# NVM Register Definitions: IP-XACT component
VLNV meklort:<PROJECT>:NVM Register Definitions:1.0

## Address spaces and blocks
NVM.NVM: base 0xC0007000, range , width , register

## Registers
Registers are 32-bit, read-write, no defined reset value unless marked. A register's access mark holds for its fields unless they carry their own. Offsets are from the block's base; lines under a group give offsets from that group; [hi:lo] are bit positions; {n}, {i} and the like mark numbered series; 'fields as' and 'values as' point back to an identical list; <NAME> marks a mode.

## NVM.NVM — Device Registers
Base 0xC0007000
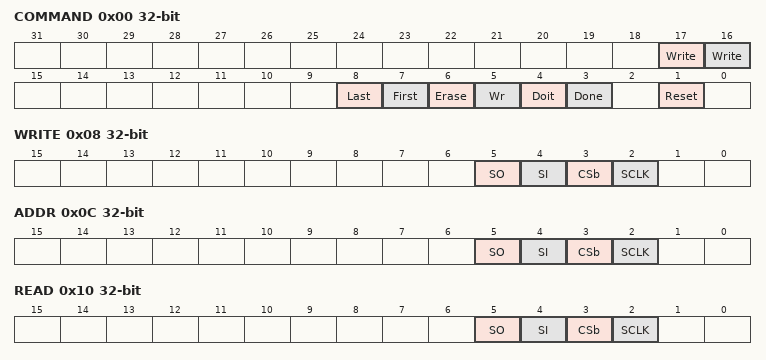
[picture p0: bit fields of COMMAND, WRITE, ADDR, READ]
0x00 COMMAND
  [17] Write Disable Command — The write disable command bit. Set '1' will make the flash interface state machine generate a write disable command cycle to the flash device to clear the write enable bit in the device status register. This command is used for devices with a write protection function.
  [16] Write Enable Command — The write enable command bit. Set '1' will make the flash interface state machine generate a write enable command cycle to the flash device to set the write enable bit in the device status register. This command is used for devices with a write protection function.
  [8] Last — When this bit is set, the next command sequence is interpreted as the last one of a burst and any cleanup work is done.
  [7] First — This bit is passed to the SEE_FSM or SPI_FSM if the pass_mode bit is set
  [6] Erase — The erase command bit. Set high to execute an erase. This bit is ignored if the wr is clear.
  [5] Wr — The write/not read command bit. Set to execute write or erase.
  [4] Doit — Command from software to start the defined command. The done bit must be clear before setting this bit. This bit is self clearing and will remain set while the command is active.
  [3] Done — Sequence completion bit that is asserted when the command requested by assertion of the doit bit has completed.
  [1] Reset — When set, the entire NVM state machine is reset. This bit is self- clearing.
0x08 WRITE — 32bits of write data are used when write commands are executed.
  [5] SO Output Value — When in bit-bang mode, this bit controls the SO output value.
  [4] SI Output Value — When in bit-bang mode, this bit controls the SI output value.
  [3] CSb Output Value — When in bit-bang mode, this bit controls the CSb output value.
  [2] SCLK Output Value — When in bit-bang mode, this bit controls the SCLK output value.
0x0C ADDR — The 24 bit address for a read or write operation (must be 4 byte aligned).
  [5] SO Output Disable — When in bit-bang mode, this bit controls the SO output enable.
  [4] SI Output Disable — When in bit-bang mode, this bit controls the SI output enable.
  [3] CSb Output Disable — When in bit-bang mode, this bit controls the CSb output enable.
  [2] SCLK Output Disable — When in bit-bang mode, this bit controls the SCLK output enable.
0x10 READ — 32bits of read data are used when read commands are executed.
  [5] SO Input Value — When in bit-bang mode, this bit reads the current SO input value.
  [4] SI Input Value — When in bit-bang mode, this bit reads the current SI input value.
  [3] CSb Input Value — When in bit-bang mode, this bit reads the current CSb input value.
  [2] SCLK Input Value — When in bit-bang mode, this bit reads the current SCLK input value.
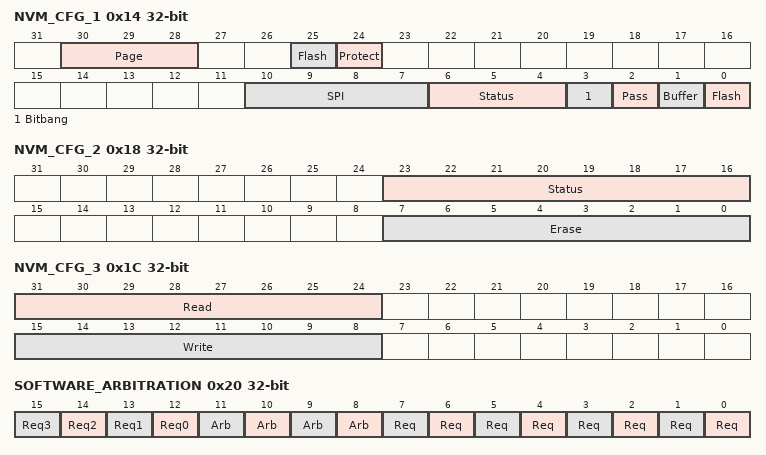
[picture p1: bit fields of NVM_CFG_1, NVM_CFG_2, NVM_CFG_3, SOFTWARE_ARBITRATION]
0x14 NVM_CFG_1
  [30:28] Page Size — These bits indicate the page size of the attached flash device. They are set automatically depending on the chosen flash as indicated by the strapping option pins.
    0=256 bytes; 1=512 bytes; 2=1024 bytes; 3=2048 bytes; 4=4096 bytes; 5=264 bytes
  [25] Flash Size — Enables 1-Mbit devices as opposed to 512 Kbit. At CORE reset, this pin is set to the value of the SO pin.
  [24] Protect Mode
  [10:7] SPI CLK DIV — The equation to calculate the clock freq. for SCK is: CORE_CLK / ((SPI_CLK_DIV + 1) * 2)
  [6:4] Status Bit — Bit Offset in status command response to interpret as the ready flag.
  [3] Bitbang Mode — Enable bit-bang mode to control pins.
  [2] Pass Mode — Enable pass-thorough mode to the byte level SPI and SEE state machines.
  [1] Buffer Mode — Enable SSRAM Buffered Interface mode.
  [0] Flash Mode — Enable Flash Interface mode.
0x18 NVM_CFG_2
  [23:16] Status Command — This is the Flash status register read command.
  [7:0] Erase Command — This is the Flash page erase command.
0x1C NVM_CFG_3
  [31:24] Read Command — This is the Flash/SEEPROM read command. Following this command, any number of bytes may be read up to the end of the flash memory.
  [15:8] Write Command — Command to write a series of bytes into a selected page in the Flash device. Note: this write command wraps around to the beginning of the page after the internal address counter in the Flash device reaches the end of the page.
0x20 SOFTWARE_ARBITRATION
  [n+12] Req{n} (n=0..3) — This is the status of requester {n}. When this bit is one, it means that Req Set{n} has been set since Req Clr{n}.
  [n+8] Arb Won{n} (n=0..3) — When arbitration is won, this bit will be read as 1, when an operation is complete, then the Req Clr{n} must be written to clear this bit.
  [n+4] Req Clr{n} (n=0..3) — Clear Software Arbitration request Bit {n}. This bit is cleared by writing a 1 to this bit position.
  [n] Req Set{n} (n=0..3) — Set Software Arbitration request Bit {n}. This bit is set by writing a 1 to this bit position.
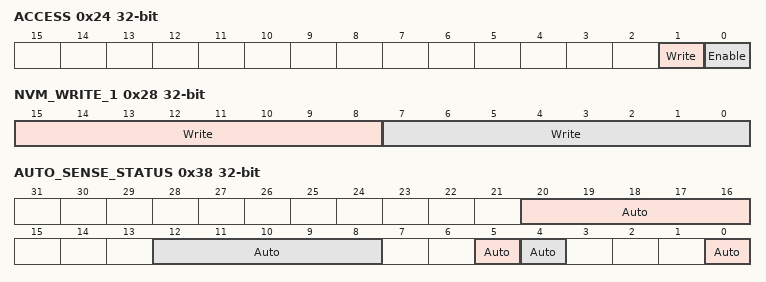
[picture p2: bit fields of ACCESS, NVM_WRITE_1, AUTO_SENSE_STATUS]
0x24 ACCESS
  [1] Write Enable — When 0, prevents write access to all other NVRAM registers, except for the Software arbitration register.
  [0] Enable — When 1, allows the NVRAM write command to be issued even if the NVRAM write enable bit 21 of the mode control register 0x6800.
0x28 NVM_WRITE_1
  [15:8] Write Disable Command — Flash write disable command when device with protection function is used. This command will be issued by the flash interface state machine through SPI interface.
  [7:0] Write Enable Command — Flash write enable command when device with protection function is used. This command will be issued by the flash interface state machine through SPI interface.
0x2C ARBITRATION_WATCHDOG
0x38 AUTO_SENSE_STATUS
  [20:16] Auto Detected Device ID
    4=AT45DB011D; 3=AT45DB021D; 0=AT45DB041D; 11=STM25PE10; 10=STM25PE20; 8=STM25PE40; 12=STM45PE10; 13=STM45PE20; 14=STM45PE40
  [12:8] Auto Config State — Auto Config FSM state.
  [5] Auto Config Successful — Auto config is successful.
  [4] Auto Config Enable — Auto config feature is enabled through pin strap.
  [0] Auto Config Busy — Auto Configuration Busy
